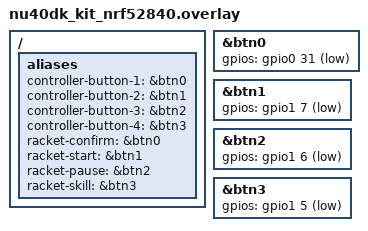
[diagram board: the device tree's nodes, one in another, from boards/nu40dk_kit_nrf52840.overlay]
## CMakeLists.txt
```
cmake_minimum_required(VERSION 3.20)
option(DT_ZEPHYR_APP "Build the board application instead of host tests" OFF)
option(DT_IMU_TRACE "Developer UART trace; disabled in ordinary builds" OFF)
if(DT_ZEPHYR_APP)
  set(BOARD_ROOT ${CMAKE_CURRENT_SOURCE_DIR})
  list(APPEND DTS_ROOT ${CMAKE_CURRENT_SOURCE_DIR})
  find_package(Zephyr REQUIRED HINTS $ENV{ZEPHYR_BASE})
endif()
project(digital_tennis_firmware C)
find_package(Python3 REQUIRED COMPONENTS Interpreter)
set_property(DIRECTORY APPEND PROPERTY CMAKE_CONFIGURE_DEPENDS ${CMAKE_CURRENT_SOURCE_DIR}/config/gesture-rules.csv ${CMAKE_CURRENT_SOURCE_DIR}/config/gesture-detector.csv ${CMAKE_CURRENT_SOURCE_DIR}/tools/generate-gesture-rules.py)
execute_process(COMMAND ${Python3_EXECUTABLE} ${CMAKE_CURRENT_SOURCE_DIR}/tools/generate-gesture-rules.py ${CMAKE_CURRENT_SOURCE_DIR}/config/gesture-rules.csv ${CMAKE_CURRENT_BINARY_DIR}/generated/dt_gesture_rules.h ${CMAKE_CURRENT_SOURCE_DIR}/config/gesture-detector.csv RESULT_VARIABLE gesture_result)
if(NOT gesture_result EQUAL 0)
  message(FATAL_ERROR "Invalid gesture rules CSV")
endif()
if(NOT DT_PROTOCOL_ROOT)
  include(FetchContent)
  FetchContent_Declare(protocol GIT_REPOSITORY https://github.com/digital-tennis/digital-tennis-protocol.git GIT_TAG 2bb3f0e80a9280458ccfe087201504a4613994e7 GIT_SHALLOW FALSE)
  FetchContent_MakeAvailable(protocol)
else()
  add_subdirectory(${DT_PROTOCOL_ROOT} protocol)
endif()
add_library(dt_controller STATIC src/ap/dt_controller.c src/ap/dt_tx_queue.c src/ap/dt_button.c src/ap/dt_gesture.c)
target_include_directories(dt_controller PUBLIC src/common)
target_include_directories(dt_controller PRIVATE ${CMAKE_CURRENT_BINARY_DIR}/generated)
target_link_libraries(dt_controller PUBLIC dt_protocol)
target_compile_options(dt_controller PRIVATE -Wall -Wextra -Werror)
if(DT_ZEPHYR_APP)
  target_link_libraries(dt_protocol PUBLIC zephyr_interface)
  target_link_libraries(dt_controller PUBLIC zephyr_interface)
  if(BOARD MATCHES "^nu54v_dk(/|$)")
    target_compile_definitions(app PRIVATE DT_BUTTON_PROFILE=1)
  endif()
  target_sources(app PRIVATE src/main.c src/hw/driver/external_imu.c src/hw/driver/lsm6ds3tr_c.c src/hw/driver/buttons.c src/ap/ble_peripheral.c)
  if(DT_IMU_TRACE)
    target_compile_definitions(app PRIVATE DT_IMU_TRACE=1)
    target_sources(app PRIVATE src/hw/driver/imu_trace.c)
  endif()
  target_link_libraries(app PRIVATE dt_controller)
else()
  enable_testing()
  add_executable(lsm6ds3tr_c_checks tests/lsm6ds3tr_c_checks.c src/hw/driver/lsm6ds3tr_c.c)
  target_include_directories(lsm6ds3tr_c_checks PRIVATE src/common)
  target_compile_options(lsm6ds3tr_c_checks PRIVATE -Wall -Wextra -Werror -UNDEBUG)
  target_link_libraries(lsm6ds3tr_c_checks PRIVATE m)
  add_test(NAME lsm6ds3tr_c_register_adapter COMMAND lsm6ds3tr_c_checks)
  add_executable(controller_checks tests/controller_checks.c)
  target_link_libraries(controller_checks PRIVATE dt_controller m)
  target_compile_options(controller_checks PRIVATE -Wall -Wextra -Werror -UNDEBUG)
  add_test(NAME external_imu_pipeline COMMAND controller_checks)
  add_executable(transport_checks tests/transport_checks.c)
  target_link_libraries(transport_checks PRIVATE dt_controller m)
  target_compile_options(transport_checks PRIVATE -Wall -Wextra -Werror -UNDEBUG)
  add_test(NAME transport_and_buttons COMMAND transport_checks)
  add_executable(peak_checks tests/peak_checks.c)
  target_link_libraries(peak_checks PRIVATE dt_controller m)
  target_compile_options(peak_checks PRIVATE -Wall -Wextra -Werror -UNDEBUG)
  add_test(NAME acceleration_peak_pipeline COMMAND peak_checks)
  add_executable(imu_replay tools/imu_replay.c)
  target_link_libraries(imu_replay PRIVATE dt_controller m)
  target_compile_options(imu_replay PRIVATE -Wall -Wextra -Werror)
  find_package(Python3 REQUIRED COMPONENTS Interpreter)
  add_test(NAME imu_capture_replay COMMAND ${Python3_EXECUTABLE} ${CMAKE_CURRENT_SOURCE_DIR}/tests/replay_checks.py $<TARGET_FILE:imu_replay>)
  add_executable(physical_checks tests/physical_checks.c)
  target_link_libraries(physical_checks PRIVATE dt_controller m)
  target_compile_options(physical_checks PRIVATE -Wall -Wextra -Werror -UNDEBUG)
  add_test(NAME physical_event_boundaries COMMAND physical_checks)
  add_executable(gesture_checks tests/gesture_checks.c)
  target_link_libraries(gesture_checks PRIVATE dt_controller m)
  target_compile_options(gesture_checks PRIVATE -Wall -Wextra -Werror -UNDEBUG)
  add_test(NAME tennis_gesture_features COMMAND gesture_checks)
  add_test(NAME kinematic_virtual_imu COMMAND ${Python3_EXECUTABLE} ${CMAKE_CURRENT_SOURCE_DIR}/tests/simulator_checks.py $<TARGET_FILE:imu_replay>)
  add_test(NAME threshold_study_boundaries COMMAND ${Python3_EXECUTABLE} ${CMAKE_CURRENT_SOURCE_DIR}/tests/threshold_checks.py $<TARGET_FILE:imu_replay>)
endif()
```

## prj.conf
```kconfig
CONFIG_BT=y
CONFIG_BT_PERIPHERAL=y
CONFIG_BT_DEVICE_NAME="Digital Tennis Racket"
CONFIG_BT_SMP=y
CONFIG_BT_MAX_CONN=1
CONFIG_SENSOR=y
CONFIG_I2C=y
CONFIG_SPI=y
CONFIG_LOG=y
CONFIG_MAIN_STACK_SIZE=4096
CONFIG_SYSTEM_WORKQUEUE_STACK_SIZE=2048

CONFIG_GPIO=y
CONFIG_FLASH=y
CONFIG_FLASH_MAP=y
CONFIG_NVS=y
CONFIG_SETTINGS=y
CONFIG_BT_SETTINGS=y

CONFIG_BT_BONDABLE=y
# Screenless racket: SC encryption + bonding, without PIN/MITM authentication.
# Explicitly approved for the NU54 Tennis test device on 2026-10-18.
CONFIG_BT_SMP_SC_PAIR_ONLY=y
```

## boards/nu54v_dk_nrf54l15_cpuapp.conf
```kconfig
# NU54 uses RRAM/ZMS. No IMU alias is enabled in this validation target.
CONFIG_NVS=n
CONFIG_ZMS=y
CONFIG_SETTINGS_ZMS=y
CONFIG_BT_DEVICE_NAME="Digital Tennis NU54"

# Separate Tennis identity avoids reusing the reference app GATT/security cache.
CONFIG_BT_ID_MAX=2
```

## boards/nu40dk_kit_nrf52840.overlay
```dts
/* Application adaptation of nu40dk-kit df4367ed: upstream button.c uses _DEF_LOW.
 * Preserve the vendored DTS and express the logical active-low level here.
 */
/ {
    aliases {
        controller-button-1 = &btn0;
        controller-button-2 = &btn1;
        controller-button-3 = &btn2;
        controller-button-4 = &btn3;

        racket-confirm = &btn0;
        racket-start = &btn1;
        racket-pause = &btn2;
        racket-skill = &btn3;
    };
};
&btn0 { gpios = <&gpio0 31 (GPIO_PULL_UP | GPIO_ACTIVE_LOW)>; };
&btn1 { gpios = <&gpio1 7 (GPIO_PULL_UP | GPIO_ACTIVE_LOW)>; };
&btn2 { gpios = <&gpio1 6 (GPIO_PULL_UP | GPIO_ACTIVE_LOW)>; };
&btn3 { gpios = <&gpio1 5 (GPIO_PULL_UP | GPIO_ACTIVE_LOW)>; };
```

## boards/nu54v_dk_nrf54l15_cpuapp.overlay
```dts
/ {
    chosen { zephyr,settings-partition = &tennis_bonds; };
    aliases {
        controller-button-1 = &button0;
        controller-button-2 = &button1;
        controller-button-3 = &button2;
        controller-button-4 = &button3;

        racket-serve = &button0;
        racket-forehand = &button1;
        racket-backhand = &button2;
        racket-skill = &button3;
    };
};

/* Separate from the reference wallet storage at 0x174000..0x17cfff.
 * Installation must first verify this reserved code-slot tail is unused/blank.
 * Never erase or mount the reference wallet storage as a Tennis settings volume.
 */
&cpuapp_rram {
    partitions {
        tennis_bonds: partition@168000 {
            compatible = "zephyr,mapped-partition";
            label = "digital-tennis-bonds";
            reg = <0x168000 0x8000>;
        };
    };
};
```

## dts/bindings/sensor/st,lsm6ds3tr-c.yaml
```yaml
description: LSM6DS3TR-C external six-axis IMU, polled by the Digital Tennis application
compatible: "st,lsm6ds3tr-c"
include: i2c-device.yaml
```

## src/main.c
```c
#include "dt_ble.h"
#include "dt_sample_clock.h"
#include <zephyr/kernel.h>
#include <zephyr/logging/log.h>
LOG_MODULE_REGISTER(digital_tennis,LOG_LEVEL_INF);
dt_controller dt_app_controller;
K_MUTEX_DEFINE(dt_app_mutex);
extern bool dt_external_imu_read(void *context,dt_imu_sample *sample);
int main(void){
 if(!dt_controller_init(&dt_app_controller,(dt_imu_port){NULL,dt_external_imu_read},dt_motion_physical_defaults()))return -1;
 #ifdef DT_BUTTON_PROFILE
 dt_app_controller.input_profile=DT_INPUT_PHYSICAL_BUTTONS;
 LOG_INF("Physical buttons 1..4: down/up only; IMU unused.");
 #endif
 dt_buttons_init();int error=dt_ble_start();if(error){LOG_ERR("BLE initialization failed: %d",error);return error;}
 LOG_INF("BLE link probe works without a sensor; external IMU calibration remains required for swings.");
 dt_sample_clock sample_clock={0};
 for(;;){
  dt_packet input,output;uint32_t epoch;
  for(unsigned i=0;i<4&&dt_ble_receive(&input,&epoch);i++){
   k_mutex_lock(&dt_app_mutex,K_FOREVER);bool reply=dt_controller_command(&dt_app_controller,&input,(uint32_t)k_uptime_get(),&output);k_mutex_unlock(&dt_app_mutex);
   if(reply)dt_ble_send(&output,epoch);
  }
  bool emit=false;
  if(dt_sample_due(&sample_clock,(uint32_t)k_uptime_get())){
   epoch=dt_ble_epoch();k_mutex_lock(&dt_app_mutex,K_FOREVER);emit=dt_controller_tick(&dt_app_controller,&output);k_mutex_unlock(&dt_app_mutex);if(emit)dt_ble_send(&output,epoch);
  }
  epoch=dt_ble_epoch();k_mutex_lock(&dt_app_mutex,K_FOREVER);emit=dt_buttons_poll(&dt_app_controller,(uint32_t)k_uptime_get(),&output);k_mutex_unlock(&dt_app_mutex);if(emit)dt_ble_send(&output,epoch);
  k_sleep(K_MSEC(1));
 }
}
```
